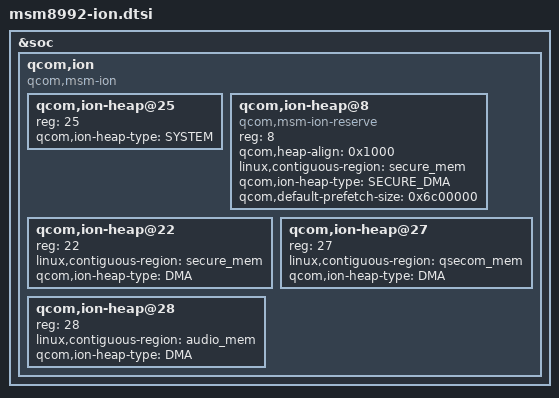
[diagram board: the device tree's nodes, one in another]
/* Copyright (c) 2014-2016, The Linux Foundation. All rights reserved.
 *
 * This program is free software; you can redistribute it and/or modify
 * it under the terms of the GNU General Public License version 2 and
 * only version 2 as published by the Free Software Foundation.
 *
 * This program is distributed in the hope that it will be useful,
 * but WITHOUT ANY WARRANTY; without even the implied warranty of
 * MERCHANTABILITY or FITNESS FOR A PARTICULAR PURPOSE.  See the
 * GNU General Public License for more details.
 */

&soc {
	qcom,ion {
		compatible = "qcom,msm-ion";
		#address-cells = <1>;
		#size-cells = <0>;

		qcom,ion-heap@25 {
			reg = <25>;
			qcom,ion-heap-type = "SYSTEM";
		};

		qcom,ion-heap@8 { /* CP_MM HEAP */
			compatible = "qcom,msm-ion-reserve";
			reg = <8>;
			qcom,heap-align = <0x1000>;
			linux,contiguous-region = <&secure_mem>;
			qcom,ion-heap-type = "SECURE_DMA";
			qcom,default-prefetch-size = <0x6c00000>;
		};

		qcom,ion-heap@22 { /* adsp heap */
			reg = <22>;
			linux,contiguous-region = <&secure_mem>;
			qcom,ion-heap-type = "DMA";
		};

		qcom,ion-heap@27 { /* QSECOM HEAP */
			reg = <27>;
			linux,contiguous-region = <&qsecom_mem>;
			qcom,ion-heap-type = "DMA";
		};

		qcom,ion-heap@28 { /* AUDIO HEAP */
			reg = <28>;
			linux,contiguous-region = <&audio_mem>;
			qcom,ion-heap-type = "DMA";
		};
	};
};
